VERSION ""

NS_ :

BS_:

BU_: Minieye ADAS

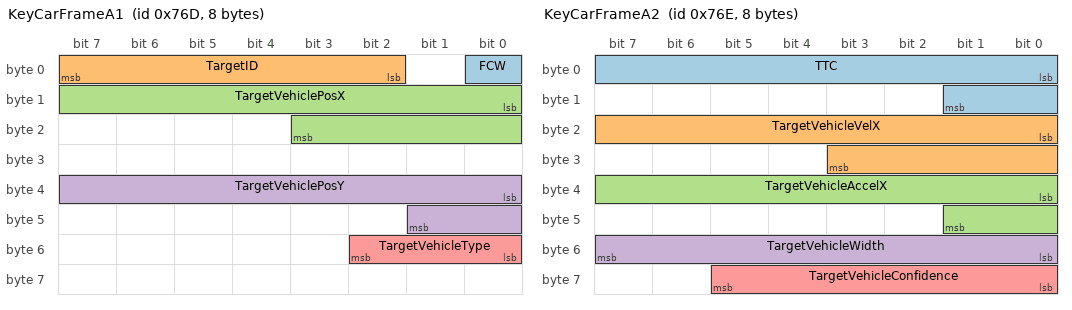
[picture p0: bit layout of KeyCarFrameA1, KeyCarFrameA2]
BO_ 1901 KeyCarFrameA1: 8 MINIEYE_TRANSMITTER
 SG_ FCW : 0|1@1+ (1,0) [0|1] "" Vector__XXX
 SG_ TargetID : 2|6@1+ (1,0) [0|63] "" Vector__XXX
 SG_ TargetVehiclePosX : 8|12@1+ (0.0625,0) [0|250] "Meter" Vector__XXX
 SG_ TargetVehiclePosY : 32|10@1- (0.0625,0) [-31.9375|31.9375] "Meter" Vector__XXX
 SG_ TargetVehicleType : 48|3@1+ (1,0) [0|5] "" Vector__XXX

BO_ 1902 KeyCarFrameA2: 8 MINIEYE_TRANSMITTER
 SG_ TTC : 0|10@1+ (0.01,0) [0|10] "Second" Vector__XXX
 SG_ TargetVehicleVelX : 16|12@1- (0.0625,0) [-127.93|127.93] "M/Sec" Vector__XXX
 SG_ TargetVehicleAccelX : 32|10@1- (0.03,0) [-14.97|14.97] "M/Sec^2" Vector__XXX
 SG_ TargetVehicleWidth : 48|8@1+ (0.05,0) [0|1.25] "M" Vector__XXX
 SG_ TargetVehicleConfidence : 56|6@1+ (0.02,0) [0|1] "" Vector__XXX

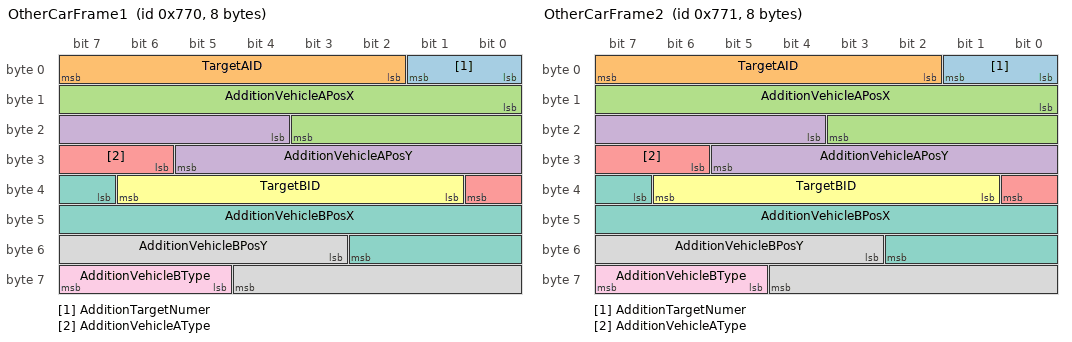
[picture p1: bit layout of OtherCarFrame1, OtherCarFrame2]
BO_ 1904 OtherCarFrame1: 8 MINIEYE_TRANSMITTER
 SG_ AdditionTargetNumer : 0|2@1+ (1,0) [0|2] "" Vector__XXX
 SG_ TargetAID : 2|6@1+ (1,0) [0|63] "" Vector__XXX
 SG_ AdditionVehicleAPosX : 8|12@1+ (0.0625,0) [0|250] "Meter" Vector__XXX
 SG_ AdditionVehicleAPosY : 20|10@1- (0.0625,0) [-31.9375|31.9375] "Meter" Vector__XXX
 SG_ AdditionVehicleAType : 30|3@1+ (1,0) [0|5] "" Vector__XXX
 SG_ TargetBID : 33|6@1+ (1,0) [0|63] "" Vector__XXX
 SG_ AdditionVehicleBPosX : 39|12@1+ (0.0625,0) [0|250] "Meter" Vector__XXX
 SG_ AdditionVehicleBPosY : 51|10@1- (0.0625,0) [-31.9375|31.9375] "Meter" Vector__XXX
 SG_ AdditionVehicleBType : 61|3@1+ (1,0) [0|5] "" Vector__XXX

BO_ 1905 OtherCarFrame2: 8 MINIEYE_TRANSMITTER
 SG_ AdditionTargetNumer : 0|2@1+ (1,0) [0|2] "" Vector__XXX
 SG_ TargetAID : 2|6@1+ (1,0) [0|63] "" Vector__XXX
 SG_ AdditionVehicleAPosX : 8|12@1+ (0.0625,0) [0|250] "Meter" Vector__XXX
 SG_ AdditionVehicleAPosY : 20|10@1- (0.0625,0) [-31.9375|31.9375] "Meter" Vector__XXX
 SG_ AdditionVehicleAType : 30|3@1+ (1,0) [0|5] "" Vector__XXX
 SG_ TargetBID : 33|6@1+ (1,0) [0|63] "" Vector__XXX
 SG_ AdditionVehicleBPosX : 39|12@1+ (0.0625,0) [0|250] "Meter" Vector__XXX
 SG_ AdditionVehicleBPosY : 51|10@1- (0.0625,0) [-31.9375|31.9375] "Meter" Vector__XXX
 SG_ AdditionVehicleBType : 61|3@1+ (1,0) [0|5] "" Vector__XXX

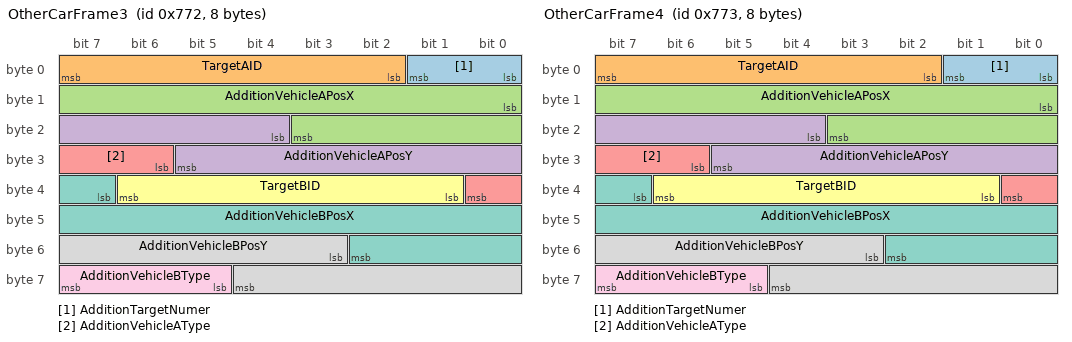
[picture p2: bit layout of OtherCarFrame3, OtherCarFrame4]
BO_ 1906 OtherCarFrame3: 8 MINIEYE_TRANSMITTER
 SG_ AdditionTargetNumer : 0|2@1+ (1,0) [0|2] "" Vector__XXX
 SG_ TargetAID : 2|6@1+ (1,0) [0|63] "" Vector__XXX
 SG_ AdditionVehicleAPosX : 8|12@1+ (0.0625,0) [0|250] "Meter" Vector__XXX
 SG_ AdditionVehicleAPosY : 20|10@1- (0.0625,0) [-31.9375|31.9375] "Meter" Vector__XXX
 SG_ AdditionVehicleAType : 30|3@1+ (1,0) [0|5] "" Vector__XXX
 SG_ TargetBID : 33|6@1+ (1,0) [0|63] "" Vector__XXX
 SG_ AdditionVehicleBPosX : 39|12@1+ (0.0625,0) [0|250] "Meter" Vector__XXX
 SG_ AdditionVehicleBPosY : 51|10@1- (0.0625,0) [-31.9375|31.9375] "Meter" Vector__XXX
 SG_ AdditionVehicleBType : 61|3@1+ (1,0) [0|5] "" Vector__XXX

BO_ 1907 OtherCarFrame4: 8 MINIEYE_TRANSMITTER
 SG_ AdditionTargetNumer : 0|2@1+ (1,0) [0|2] "" Vector__XXX
 SG_ TargetAID : 2|6@1+ (1,0) [0|63] "" Vector__XXX
 SG_ AdditionVehicleAPosX : 8|12@1+ (0.0625,0) [0|250] "Meter" Vector__XXX
 SG_ AdditionVehicleAPosY : 20|10@1- (0.0625,0) [-31.9375|31.9375] "Meter" Vector__XXX
 SG_ AdditionVehicleAType : 30|3@1+ (1,0) [0|5] "" Vector__XXX
 SG_ TargetBID : 33|6@1+ (1,0) [0|63] "" Vector__XXX
 SG_ AdditionVehicleBPosX : 39|12@1+ (0.0625,0) [0|250] "Meter" Vector__XXX
 SG_ AdditionVehicleBPosY : 51|10@1- (0.0625,0) [-31.9375|31.9375] "Meter" Vector__XXX
 SG_ AdditionVehicleBType : 61|3@1+ (1,0) [0|5] "" Vector__XXX

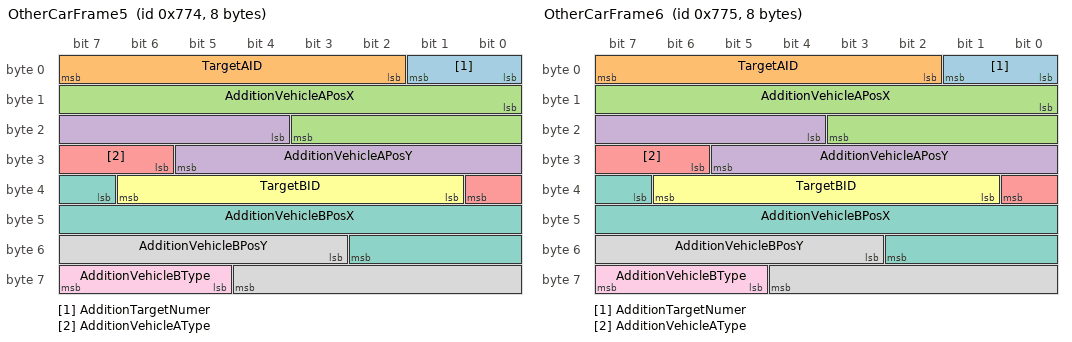
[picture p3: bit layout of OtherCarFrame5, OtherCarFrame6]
BO_ 1908 OtherCarFrame5: 8 MINIEYE_TRANSMITTER
 SG_ AdditionTargetNumer : 0|2@1+ (1,0) [0|2] "" Vector__XXX
 SG_ TargetAID : 2|6@1+ (1,0) [0|63] "" Vector__XXX
 SG_ AdditionVehicleAPosX : 8|12@1+ (0.0625,0) [0|250] "Meter" Vector__XXX
 SG_ AdditionVehicleAPosY : 20|10@1- (0.0625,0) [-31.9375|31.9375] "Meter" Vector__XXX
 SG_ AdditionVehicleAType : 30|3@1+ (1,0) [0|5] "" Vector__XXX
 SG_ TargetBID : 33|6@1+ (1,0) [0|63] "" Vector__XXX
 SG_ AdditionVehicleBPosX : 39|12@1+ (0.0625,0) [0|250] "Meter" Vector__XXX
 SG_ AdditionVehicleBPosY : 51|10@1- (0.0625,0) [-31.9375|31.9375] "Meter" Vector__XXX
 SG_ AdditionVehicleBType : 61|3@1+ (1,0) [0|5] "" Vector__XXX

BO_ 1909 OtherCarFrame6: 8 MINIEYE_TRANSMITTER
 SG_ AdditionTargetNumer : 0|2@1+ (1,0) [0|2] "" Vector__XXX
 SG_ TargetAID : 2|6@1+ (1,0) [0|63] "" Vector__XXX
 SG_ AdditionVehicleAPosX : 8|12@1+ (0.0625,0) [0|250] "Meter" Vector__XXX
 SG_ AdditionVehicleAPosY : 20|10@1- (0.0625,0) [-31.9375|31.9375] "Meter" Vector__XXX
 SG_ AdditionVehicleAType : 30|3@1+ (1,0) [0|5] "" Vector__XXX
 SG_ TargetBID : 33|6@1+ (1,0) [0|63] "" Vector__XXX
 SG_ AdditionVehicleBPosX : 39|12@1+ (0.0625,0) [0|250] "Meter" Vector__XXX
 SG_ AdditionVehicleBPosY : 51|10@1- (0.0625,0) [-31.9375|31.9375] "Meter" Vector__XXX
 SG_ AdditionVehicleBType : 61|3@1+ (1,0) [0|5] "" Vector__XXX

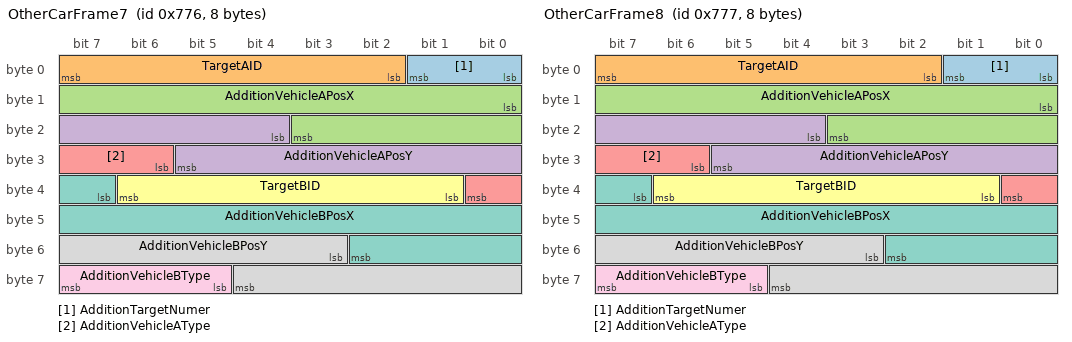
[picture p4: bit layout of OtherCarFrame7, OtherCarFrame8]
BO_ 1910 OtherCarFrame7: 8 MINIEYE_TRANSMITTER
 SG_ AdditionTargetNumer : 0|2@1+ (1,0) [0|2] "" Vector__XXX
 SG_ TargetAID : 2|6@1+ (1,0) [0|63] "" Vector__XXX
 SG_ AdditionVehicleAPosX : 8|12@1+ (0.0625,0) [0|250] "Meter" Vector__XXX
 SG_ AdditionVehicleAPosY : 20|10@1- (0.0625,0) [-31.9375|31.9375] "Meter" Vector__XXX
 SG_ AdditionVehicleAType : 30|3@1+ (1,0) [0|5] "" Vector__XXX
 SG_ TargetBID : 33|6@1+ (1,0) [0|63] "" Vector__XXX
 SG_ AdditionVehicleBPosX : 39|12@1+ (0.0625,0) [0|250] "Meter" Vector__XXX
 SG_ AdditionVehicleBPosY : 51|10@1- (0.0625,0) [-31.9375|31.9375] "Meter" Vector__XXX
 SG_ AdditionVehicleBType : 61|3@1+ (1,0) [0|5] "" Vector__XXX

BO_ 1911 OtherCarFrame8: 8 MINIEYE_TRANSMITTER
 SG_ AdditionTargetNumer : 0|2@1+ (1,0) [0|2] "" Vector__XXX
 SG_ TargetAID : 2|6@1+ (1,0) [0|63] "" Vector__XXX
 SG_ AdditionVehicleAPosX : 8|12@1+ (0.0625,0) [0|250] "Meter" Vector__XXX
 SG_ AdditionVehicleAPosY : 20|10@1- (0.0625,0) [-31.9375|31.9375] "Meter" Vector__XXX
 SG_ AdditionVehicleAType : 30|3@1+ (1,0) [0|5] "" Vector__XXX
 SG_ TargetBID : 33|6@1+ (1,0) [0|63] "" Vector__XXX
 SG_ AdditionVehicleBPosX : 39|12@1+ (0.0625,0) [0|250] "Meter" Vector__XXX
 SG_ AdditionVehicleBPosY : 51|10@1- (0.0625,0) [-31.9375|31.9375] "Meter" Vector__XXX
 SG_ AdditionVehicleBType : 61|3@1+ (1,0) [0|5] "" Vector__XXX

VAL_ 1901 FCW 1 "FCW On" 0 "FCW Off" ;
VAL_ 1901 TargetVehicleType 5 "Special Car" 4 "Box truck" 3 "Bus" 2 "Car" 1 "Resv1" 0 "No Vehicle" ;
VAL_ 1904 AdditionVehicleAType 5 "Special Car" 4 "Box truck" 3 "Bus" 2 "Car" 1 "Resv1" 0 "No Vehicle" ;
VAL_ 1904 AdditionVehicleBType 5 "Special Car" 4 "Box truck" 3 "Bus" 2 "Car" 1 "Resv1" 0 "No Vehicle" ;
VAL_ 1905 AdditionVehicleAType 5 "Special Car" 4 "Box truck" 3 "Bus" 2 "Car" 1 "Resv1" 0 "No Vehicle" ;
VAL_ 1905 AdditionVehicleBType 5 "Special Car" 4 "Box truck" 3 "Bus" 2 "Car" 1 "Resv1" 0 "No Vehicle" ;
VAL_ 1906 AdditionVehicleAType 5 "Special Car" 4 "Box truck" 3 "Bus" 2 "Car" 1 "Resv1" 0 "No Vehicle" ;
VAL_ 1906 AdditionVehicleBType 5 "Special Car" 4 "Box truck" 3 "Bus" 2 "Car" 1 "Resv1" 0 "No Vehicle" ;
VAL_ 1907 AdditionVehicleAType 5 "Special Car" 4 "Box truck" 3 "Bus" 2 "Car" 1 "Resv1" 0 "No Vehicle" ;
VAL_ 1907 AdditionVehicleBType 5 "Special Car" 4 "Box truck" 3 "Bus" 2 "Car" 1 "Resv1" 0 "No Vehicle" ;
VAL_ 1908 AdditionVehicleAType 5 "Special Car" 4 "Box truck" 3 "Bus" 2 "Car" 1 "Resv1" 0 "No Vehicle" ;
VAL_ 1908 AdditionVehicleBType 5 "Special Car" 4 "Box truck" 3 "Bus" 2 "Car" 1 "Resv1" 0 "No Vehicle" ;
VAL_ 1909 AdditionVehicleAType 5 "Special Car" 4 "Box truck" 3 "Bus" 2 "Car" 1 "Resv1" 0 "No Vehicle" ;
VAL_ 1909 AdditionVehicleBType 5 "Special Car" 4 "Box truck" 3 "Bus" 2 "Car" 1 "Resv1" 0 "No Vehicle" ;
VAL_ 1910 AdditionVehicleAType 5 "Special Car" 4 "Box truck" 3 "Bus" 2 "Car" 1 "Resv1" 0 "No Vehicle" ;
VAL_ 1910 AdditionVehicleBType 5 "Special Car" 4 "Box truck" 3 "Bus" 2 "Car" 1 "Resv1" 0 "No Vehicle" ;
VAL_ 1911 AdditionVehicleAType 5 "Special Car" 4 "Box truck" 3 "Bus" 2 "Car" 1 "Resv1" 0 "No Vehicle" ;
VAL_ 1911 AdditionVehicleBType 5 "Special Car" 4 "Box truck" 3 "Bus" 2 "Car" 1 "Resv1" 0 "No Vehicle" ;
